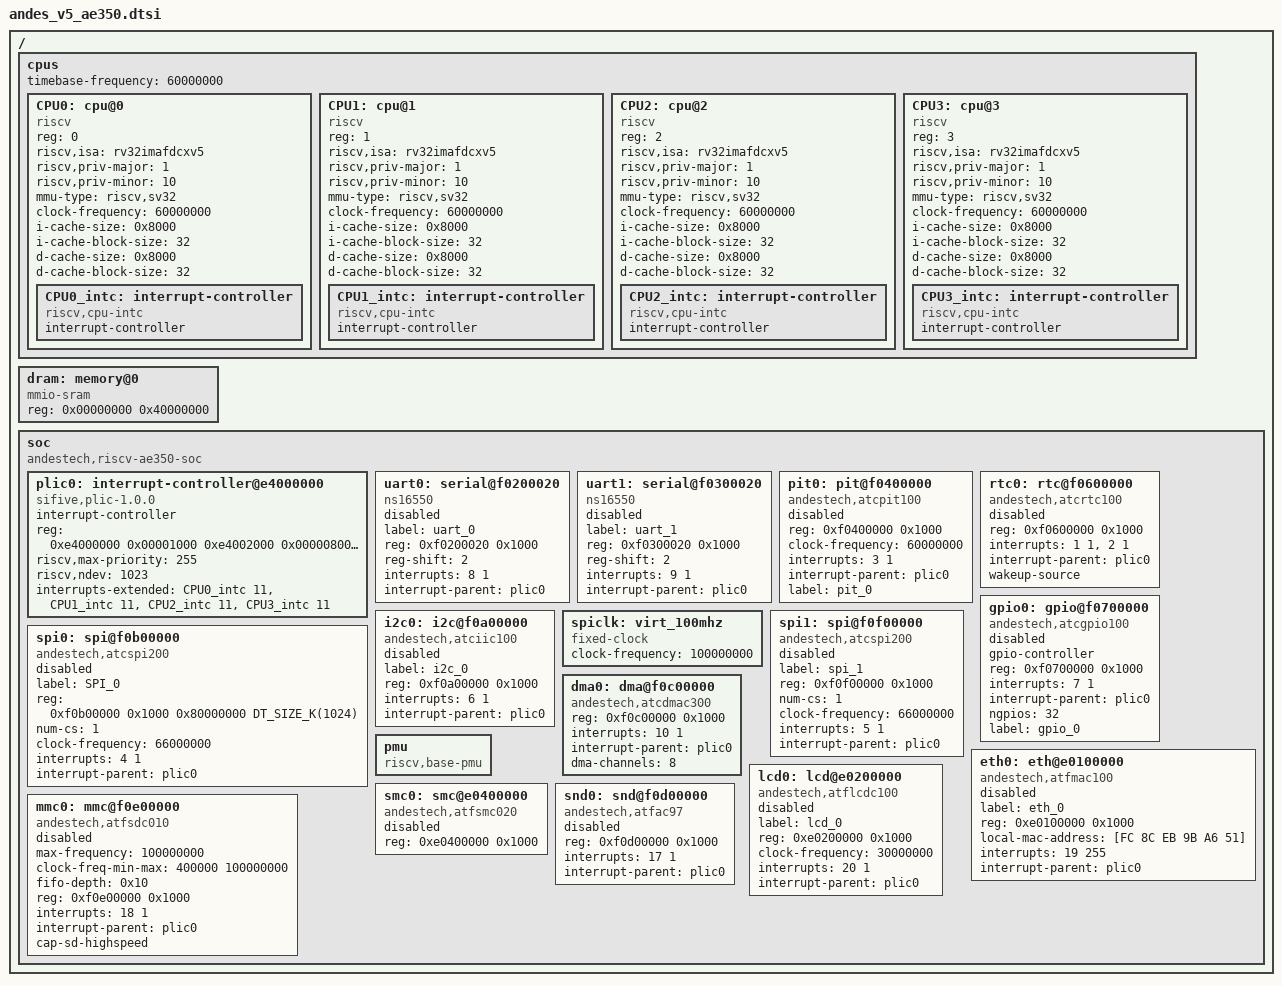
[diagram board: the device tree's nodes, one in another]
/dts-v1/;
#include <dt-bindings/gpio/gpio.h>
#include <mem.h>

/ {
	#address-cells = <1>;
	#size-cells = <1>;

	cpus {
		#address-cells = <1>;
		#size-cells = <0>;
		timebase-frequency = <60000000>;
		CPU0: cpu@0 {
			device_type = "cpu";
			reg = <0>;
			status = "okay";
			compatible = "riscv";
			riscv,isa = "rv32imafdcxv5";
			riscv,priv-major = <1>;
			riscv,priv-minor = <10>;
			mmu-type = "riscv,sv32";
			clock-frequency = <60000000>;
			i-cache-size = <0x8000>;
			i-cache-block-size = <32>;
			d-cache-size = <0x8000>;
			d-cache-block-size = <32>;
			CPU0_intc: interrupt-controller {
				#interrupt-cells = <1>;
				interrupt-controller;
				compatible = "riscv,cpu-intc";
			};
		};

		CPU1: cpu@1 {
			device_type = "cpu";
			reg = <1>;
			status = "okay";
			compatible = "riscv";
			riscv,isa = "rv32imafdcxv5";
			riscv,priv-major = <1>;
			riscv,priv-minor = <10>;
			mmu-type = "riscv,sv32";
			clock-frequency = <60000000>;
			i-cache-size = <0x8000>;
			i-cache-block-size = <32>;
			d-cache-size = <0x8000>;
			d-cache-block-size = <32>;
			CPU1_intc: interrupt-controller {
				#interrupt-cells = <1>;
				interrupt-controller;
				compatible = "riscv,cpu-intc";
			};
		};

		CPU2: cpu@2 {
			device_type = "cpu";
			reg = <2>;
			status = "okay";
			compatible = "riscv";
			riscv,isa = "rv32imafdcxv5";
			riscv,priv-major = <1>;
			riscv,priv-minor = <10>;
			mmu-type = "riscv,sv32";
			clock-frequency = <60000000>;
			i-cache-size = <0x8000>;
			i-cache-block-size = <32>;
			d-cache-size = <0x8000>;
			d-cache-block-size = <32>;
			CPU2_intc: interrupt-controller {
				#interrupt-cells = <1>;
				interrupt-controller;
				compatible = "riscv,cpu-intc";
			};
		};

		CPU3: cpu@3 {
			device_type = "cpu";
			reg = <3>;
			status = "okay";
			compatible = "riscv";
			riscv,isa = "rv32imafdcxv5";
			riscv,priv-major = <1>;
			riscv,priv-minor = <10>;
			mmu-type = "riscv,sv32";
			clock-frequency = <60000000>;
			i-cache-size = <0x8000>;
			i-cache-block-size = <32>;
			d-cache-size = <0x8000>;
			d-cache-block-size = <32>;
			CPU3_intc: interrupt-controller {
				#interrupt-cells = <1>;
				interrupt-controller;
				compatible = "riscv,cpu-intc";
			};
		};
	};

	dram: memory@0 {
		device_type = "memory";
		compatible = "mmio-sram";
		reg = <0x00000000 0x40000000>;
	};

	soc {
		#address-cells = <1>;
		#size-cells = <1>;
		compatible = "andestech,riscv-ae350-soc";
		ranges;

		plic0: interrupt-controller@e4000000 {
			compatible = "sifive,plic-1.0.0";
			#address-cells = <1>;
			#interrupt-cells = <2>;
			interrupt-controller;
			reg = <	0xe4000000 0x00001000
				0xe4002000 0x00000800
				0xe4200000 0x00010000 >;
			reg-names = "prio", "irq_en", "reg";
			riscv,max-priority = <255>;
			riscv,ndev = <1023>;
			interrupts-extended = <&CPU0_intc 11 &CPU1_intc 11
			                       &CPU2_intc 11 &CPU3_intc 11>;
		};

		uart0: serial@f0200020 {
			compatible = "ns16550";
			label = "uart_0";
			reg = <0xf0200020 0x1000>;
			reg-shift = <2>;
			interrupts = <8 1>;
			interrupt-parent = <&plic0>;
			status = "disabled";
		};

		uart1: serial@f0300020 {
			compatible = "ns16550";
			label = "uart_1";
			reg = <0xf0300020 0x1000>;
			reg-shift = <2>;
			interrupts = <9 1>;
			interrupt-parent = <&plic0>;
			status = "disabled";
		};

		pit0: pit@f0400000 {
			compatible = "andestech,atcpit100";
			reg = <0xf0400000 0x1000>;
			clock-frequency = <60000000>;
			interrupts = <3 1>;
			interrupt-parent = <&plic0>;
			label = "pit_0";
			status = "disabled";
		};

		rtc0: rtc@f0600000 {
			compatible = "andestech,atcrtc100";
			reg = <0xf0600000 0x1000>;
			interrupts = <1 1>, <2 1>;
			interrupt-parent = <&plic0>;
			wakeup-source;
			status = "disabled";
		};

		gpio0: gpio@f0700000 {
			compatible = "andestech,atcgpio100";
			gpio-controller;
			reg = <0xf0700000 0x1000>;
			interrupts = <7 1>;
			interrupt-parent = <&plic0>;
			ngpios = <32>;
			label = "gpio_0";
			status = "disabled";
			#gpio-cells = <2>;
		};

		i2c0: i2c@f0a00000 {
			compatible = "andestech,atciic100";
			label = "i2c_0";
			reg = <0xf0a00000 0x1000>;
			interrupts = <6 1>;
			interrupt-parent = <&plic0>;
			status = "disabled";
			#address-cells = <1>;
			#size-cells = <0>;
		};

		spiclk: virt_100mhz {
			#clock-cells = <0>;
			compatible = "fixed-clock";
			clock-frequency = <100000000>;
		};

		spi0: spi@f0b00000 {
			compatible = "andestech,atcspi200";
			label = "SPI_0";
			reg = <0xf0b00000 0x1000
			       0x80000000 DT_SIZE_K(1024)>;
			reg-names = "control", "mem";
			#address-cells = <1>;
			#size-cells = <0>;
			num-cs = <1>;
			clock-frequency = <66000000>;
			interrupts = <4 1>;
			interrupt-parent = <&plic0>;
			status = "disabled";
		};

		spi1: spi@f0f00000 {
			compatible = "andestech,atcspi200";
			label = "spi_1";
			reg = <0xf0f00000 0x1000>;
			reg-names = "control";
			#address-cells = <1>;
			#size-cells = <0>;
			num-cs = <1>;
			clock-frequency = <66000000>;
			interrupts = <5 1>;
			interrupt-parent = <&plic0>;
			status = "disabled";
		};

		dma0: dma@f0c00000 {
			compatible = "andestech,atcdmac300";
			reg = <0xf0c00000 0x1000>;
			interrupts = <10 1>;
			interrupt-parent = <&plic0>;
			dma-channels = <8>;
		};

		pmu {
			compatible = "riscv,base-pmu";
		};

		eth0: eth@e0100000 {
			compatible = "andestech,atfmac100";
			label = "eth_0";
			reg = <0xe0100000 0x1000>;
			local-mac-address = [FC 8C EB 9B A6 51];
			interrupts = <19 255>;
			interrupt-parent = <&plic0>;
			status = "disabled";
		};

		lcd0: lcd@e0200000 {
			compatible = "andestech,atflcdc100";
			label = "lcd_0";
			reg = <0xe0200000 0x1000>;
			clock-frequency = <30000000>;
			interrupts = <20 1>;
			interrupt-parent = <&plic0>;
			status = "disabled";
		};

		smc0: smc@e0400000 {
			compatible = "andestech,atfsmc020";
			reg = <0xe0400000 0x1000>;
			status = "disabled";
		};

		snd0: snd@f0d00000 {
			compatible = "andestech,atfac97";
			reg = <0xf0d00000 0x1000>;
			interrupts = <17 1>;
			interrupt-parent = <&plic0>;
			status = "disabled";
		};

		mmc0: mmc@f0e00000 {
			compatible = "andestech,atfsdc010";
			max-frequency = <100000000>;
			clock-freq-min-max = <400000 100000000>;
			fifo-depth = <0x10>;
			reg = <0xf0e00000 0x1000>;
			interrupts = <18 1>;
			interrupt-parent = <&plic0>;
			cap-sd-highspeed;
			status = "disabled";
		};
	};
};
